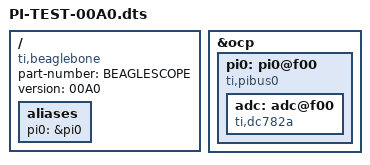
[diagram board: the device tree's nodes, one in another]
/*
 * Copyright (c) 2016 Zubeen Tolani <ZeekHuge - zeekhuge@gmail.com>
 *
 * This program is free software; you can redistribute it and/or modify it
 * under the terms of the GNU General Public License version 2 as published by
 * the Free Software Foundation.
 */

/dts-v1/;
/plugin/;

/{
    compatible = "ti,beaglebone", "ti,beaglebone-black";
    part-number = "BEAGLESCOPE";
    version = "00A0";

	aliases {
		pi0 = &pi0;
	};

    /* identification */

	fragment@0 {
		target = <&ocp>;
		__overlay__ {
			pi0: pi0@f00 {
				status="okay";
				compatible = "ti,pibus0";
				adc: adc@f00 {
					status="okay";
					compatible = "ti,dc782a";
				};
			};

		};

	};
};
